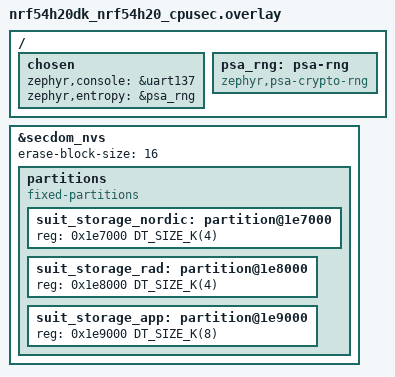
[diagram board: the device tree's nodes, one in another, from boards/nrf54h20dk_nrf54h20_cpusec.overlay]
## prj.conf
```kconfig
#
# Copyright (c) 2023 Nordic Semiconductor ASA
#
# SPDX-License-Identifier: LicenseRef-Nordic-5-Clause
#


CONFIG_ZTEST=y
CONFIG_ZTEST_NEW_API=y

CONFIG_SUIT=y
CONFIG_SUIT_UTILS=y
CONFIG_SUIT_MCI=y
CONFIG_SUIT_EXECUTION_MODE=y
CONFIG_SUIT_METADATA=y

CONFIG_ZCBOR=y
CONFIG_ZCBOR_CANONICAL=y
```

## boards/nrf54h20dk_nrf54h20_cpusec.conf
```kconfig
#
# Copyright (c) 2023 Nordic Semiconductor ASA
#
# SPDX-License-Identifier: LicenseRef-Nordic-5-Clause
#

CONFIG_NULL_POINTER_EXCEPTION_DETECTION_NONE=y
CONFIG_SERIAL=y
CONFIG_CONSOLE=y
CONFIG_UART_CONSOLE=y

# This test does not set 'IS_SECURE_DOMAIN_FW'. Hence, we need to enable the
# bare minimum configurations for running on bare metal Secure Domain.
CONFIG_SECDOM_UNIT_TEST_SUPPORT=y

# Logging and printk is using standard UART.
CONFIG_LOG_MODE_DEFERRED=y
CONFIG_LOG_BACKEND_UART=y
CONFIG_LOG_PRINTK=y
CONFIG_LOG_BUFFER_SIZE=8192


CONFIG_NULL_POINTER_EXCEPTION_DETECTION_NONE=y
CONFIG_SERIAL=y
CONFIG_CONSOLE=y
CONFIG_UART_CONSOLE=y

CONFIG_SUIT_STORAGE=y
CONFIG_SUIT_CRYPTO=y
CONFIG_SUIT_MCI_IMPL_NRF54H20_SDFW=y

CONFIG_SUIT_MPI_GENERATE=y

CONFIG_FLASH=y
```

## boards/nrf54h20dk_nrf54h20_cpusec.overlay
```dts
/*
 * Copyright (c) 2023 Nordic Semiconductor ASA
 *
 * SPDX-License-Identifier: LicenseRef-Nordic-5-Clause
 */

/ {
	chosen {
		zephyr,console = &uart137;
		zephyr,entropy = &psa_rng;
	};

	psa_rng: psa-rng {
		compatible = "zephyr,psa-crypto-rng";
		status = "okay";
	};
};

&secdom_nvs {
	erase-block-size = <16>;

	partitions {
		compatible = "fixed-partitions";
		#address-cells = <1>;
		#size-cells = <1>;

		/* Use the last 32 kB of SecDom SUIT NVM storage. */
		/* Use the first 4kB as area reserved for Secure domain. */
		suit_storage_nordic: partition@1e7000 {
			reg = <0x1e7000 DT_SIZE_K(4)>;
		};

		/* Use the next 4kB as area reserved for Radio domain. */
		suit_storage_rad: partition@1e8000 {
			reg = <0x1e8000 DT_SIZE_K(4)>;
		};

		/* Use the next 8kB as area reserved for Application domain. */
		suit_storage_app: partition@1e9000 {
			reg = <0x1e9000 DT_SIZE_K(8)>;
		};
	};
};
```

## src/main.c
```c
/*
 * Copyright (c) 2023 Nordic Semiconductor ASA
 *
 * SPDX-License-Identifier: LicenseRef-Nordic-5-Clause
 */
#include <zephyr/ztest.h>
#include <suit_mci.h>
#ifdef CONFIG_SUIT_STORAGE
#include <suit_storage.h>
#endif /* CONFIG_SUIT_STORAGE */

void test_generic_ids(void);
void test_sanity(void);
void test_api_positive_scenarios(void);
void test_topology(void);

void test_main(void)
{
#ifdef CONFIG_SUIT_STORAGE
	int ret = suit_storage_init();
	if (ret != SUIT_PLAT_SUCCESS) {
		printk("Storage init failed\n");
		return;
	}
#endif /* CONFIG_SUIT_STORAGE */

	suit_mci_init();
	test_generic_ids();
	test_sanity();
	test_api_positive_scenarios();
	test_topology();
}
```

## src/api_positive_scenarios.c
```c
/*
 * Copyright (c) 2023 Nordic Semiconductor ASA
 *
 * SPDX-License-Identifier: LicenseRef-Nordic-5-Clause
 */
#include <zephyr/ztest.h>
#include <suit_mci.h>
#ifdef CONFIG_SUIT_STORAGE
#include <suit_storage.h>
#endif /* CONFIG_SUIT_STORAGE */

#define OUTPUT_MAX_SIZE 32
static const suit_uuid_t *result_uuid[OUTPUT_MAX_SIZE];
static suit_manifest_class_info_t result_class_info[OUTPUT_MAX_SIZE];

static void *test_suit_setup(void)
{
	int ret = 0;

#ifdef CONFIG_SUIT_STORAGE
	ret = suit_storage_init();
	zassert_equal(ret, SUIT_PLAT_SUCCESS, "Unable to initialize SUIT storage");
#endif /* CONFIG_SUIT_STORAGE */

	ret = suit_mci_init();
	zassert_equal(ret, SUIT_PLAT_SUCCESS, "Unable to initialize MCI module");

	return NULL;
}

ZTEST_SUITE(mci_api_positive_scenarios_tests, NULL, test_suit_setup, NULL, NULL, NULL);

ZTEST(mci_api_positive_scenarios_tests, test_supported_manifest_class_ids_get)
{
	int rc = 0;
	size_t output_size = OUTPUT_MAX_SIZE;

	rc = suit_mci_supported_manifest_class_ids_get(result_class_info, &output_size);
	zassert_equal(rc, SUIT_PLAT_SUCCESS,
		      "suit_mci_supported_manifest_class_ids_get returned (%d)", rc);
}

ZTEST(mci_api_positive_scenarios_tests, test_invoke_order_get)
{
	int rc = 0;
	size_t output_size = OUTPUT_MAX_SIZE;

	rc = suit_mci_invoke_order_get(result_uuid, &output_size);
	zassert_equal(rc, SUIT_PLAT_SUCCESS, "suit_mci_invoke_order_get returned (%d)", rc);
}

ZTEST(mci_api_positive_scenarios_tests, test_downgrade_prevention_policy_get)
{
	int rc = 0;
	size_t output_size = OUTPUT_MAX_SIZE;

	rc = suit_mci_supported_manifest_class_ids_get(result_class_info, &output_size);
	zassert_equal(rc, SUIT_PLAT_SUCCESS,
		      "suit_mci_supported_manifest_class_ids_get returned (%d)", rc);

	for (int i = 0; i < output_size; ++i) {
		suit_downgrade_prevention_policy_t policy;

		rc = suit_mci_downgrade_prevention_policy_get(result_class_info[i].class_id,
							      &policy);
		zassert_equal(rc, SUIT_PLAT_SUCCESS,
			      "suit_mci_downgrade_prevention_policy_get returned (%d)", rc);
	}
}

ZTEST(mci_api_positive_scenarios_tests, test_independent_update_policy_get)
{
	int rc = 0;
	size_t output_size = OUTPUT_MAX_SIZE;

	rc = suit_mci_supported_manifest_class_ids_get(result_class_info, &output_size);
	zassert_equal(rc, SUIT_PLAT_SUCCESS,
		      "suit_mci_supported_manifest_class_ids_get returned (%d)", rc);

	for (int i = 0; i < output_size; ++i) {
		suit_independent_updateability_policy_t policy;

		rc = suit_mci_independent_update_policy_get(result_class_info[i].class_id, &policy);
		zassert_equal(rc, SUIT_PLAT_SUCCESS,
			      "suit_mci_independent_update_policy_get returned (%d)", rc);
	}
}

ZTEST(mci_api_positive_scenarios_tests, test_manifest_class_id_validate)
{
	int rc = 0;
	size_t output_size = OUTPUT_MAX_SIZE;

	rc = suit_mci_supported_manifest_class_ids_get(result_class_info, &output_size);
	zassert_equal(rc, SUIT_PLAT_SUCCESS,
		      "suit_mci_supported_manifest_class_ids_get returned (%d)", rc);

	for (int i = 0; i < output_size; ++i) {
		rc = suit_mci_manifest_class_id_validate(result_class_info[i].class_id);
		zassert_equal(rc, SUIT_PLAT_SUCCESS,
			      "suit_mci_manifest_class_id_validate returned (%d)", rc);
	}
}

ZTEST(mci_api_positive_scenarios_tests, test_signing_key_id_validate)
{
	int rc = 0;
	size_t output_size = OUTPUT_MAX_SIZE;

	rc = suit_mci_supported_manifest_class_ids_get(result_class_info, &output_size);
	zassert_equal(rc, SUIT_PLAT_SUCCESS,
		      "suit_mci_supported_manifest_class_ids_get returned (%d)", rc);

	for (int i = 0; i < output_size; ++i) {
		uint32_t key_id = 0;

		rc = suit_mci_signing_key_id_validate(result_class_info[i].class_id, key_id);
		zassert_true((rc == MCI_ERR_NOACCESS || rc == SUIT_PLAT_SUCCESS ||
			      rc == MCI_ERR_WRONGKEYID),
			     "suit_mci_signing_key_id_validate returned (%d)", rc);
	}
}

ZTEST(mci_api_positive_scenarios_tests, test_processor_start_rights_validate)
{
	int rc = 0;
	size_t output_size = OUTPUT_MAX_SIZE;

	rc = suit_mci_supported_manifest_class_ids_get(result_class_info, &output_size);
	zassert_equal(rc, SUIT_PLAT_SUCCESS,
		      "suit_mci_supported_manifest_class_ids_get returned (%d)", rc);

	for (int i = 0; i < output_size; ++i) {
		int processor_id = 0;

		rc = suit_mci_processor_start_rights_validate(result_class_info[i].class_id,
							      processor_id);
		zassert_true((rc == MCI_ERR_NOACCESS || rc == SUIT_PLAT_SUCCESS),
			     "suit_mci_processor_start_rights_validate returned (%d)", rc);
	}
}

ZTEST(mci_api_positive_scenarios_tests, test_memory_access_rights_validate)
{
	int rc = 0;
	size_t output_size = OUTPUT_MAX_SIZE;

	rc = suit_mci_supported_manifest_class_ids_get(result_class_info, &output_size);
	zassert_equal(rc, SUIT_PLAT_SUCCESS,
		      "suit_mci_supported_manifest_class_ids_get returned (%d)", rc);

	for (int i = 0; i < output_size; ++i) {
		void *address = &address;
		size_t mem_size = sizeof(void *);

		rc = suit_mci_memory_access_rights_validate(result_class_info[i].class_id, address,
							    mem_size);
		zassert_true((rc == MCI_ERR_NOACCESS || rc == SUIT_PLAT_SUCCESS),
			     "suit_mci_memory_access_rights_validate returned (%d)", rc);
	}
}

ZTEST(mci_api_positive_scenarios_tests, test_platform_specific_component_rights_validate)
{
	int rc = 0;
	size_t output_size = OUTPUT_MAX_SIZE;

	rc = suit_mci_supported_manifest_class_ids_get(result_class_info, &output_size);
	zassert_equal(rc, SUIT_PLAT_SUCCESS,
		      "suit_mci_supported_manifest_class_ids_get returned (%d)", rc);

	for (int i = 0; i < output_size; ++i) {
		int platform_specific_component_number = 0;

		rc = suit_mci_platform_specific_component_rights_validate(
			result_class_info[i].class_id, platform_specific_component_number);
		zassert_true((rc == MCI_ERR_NOACCESS || rc == SUIT_PLAT_SUCCESS),
			     "suit_mci_platform_specific_component_rights_validate returned (%d)",
			     rc);
	}
}

ZTEST(mci_api_positive_scenarios_tests, test_manifest_parent_child_declaration_validate)
{
	int rc = 0;
	size_t output_size = OUTPUT_MAX_SIZE;

	rc = suit_mci_supported_manifest_class_ids_get(result_class_info, &output_size);
	zassert_equal(rc, SUIT_PLAT_SUCCESS,
		      "suit_mci_supported_manifest_class_ids_get returned (%d)", rc);

	for (int i = 0; i < output_size; ++i) {
		rc = suit_mci_manifest_parent_child_declaration_validate(
			result_class_info[0].class_id, result_class_info[i].class_id);
		zassert_true((rc == MCI_ERR_NOACCESS || rc == SUIT_PLAT_SUCCESS),
			     "suit_mci_manifest_parent_child_validate returned (%d)", rc);
	}
}

ZTEST(mci_api_positive_scenarios_tests, test_manifest_process_dependency_validate)
{
	int rc = 0;
	size_t output_size = OUTPUT_MAX_SIZE;

	rc = suit_mci_supported_manifest_class_ids_get(result_class_info, &output_size);
	zassert_equal(rc, SUIT_PLAT_SUCCESS,
		      "suit_mci_supported_manifest_class_ids_get returned (%d)", rc);

	for (int i = 0; i < output_size; ++i) {
		rc = suit_mci_manifest_process_dependency_validate(result_class_info[0].class_id,
								   result_class_info[i].class_id);
		zassert_true((rc == MCI_ERR_NOACCESS || rc == SUIT_PLAT_SUCCESS),
			     "suit_mci_manifest_parent_child_validate returned (%d)", rc);
	}
}

ZTEST(mci_api_positive_scenarios_tests, test_vendor_id_for_manifest_class_id_get)
{
	int rc = 0;
	size_t output_size = OUTPUT_MAX_SIZE;

	rc = suit_mci_supported_manifest_class_ids_get(result_class_info, &output_size);
	zassert_equal(rc, SUIT_PLAT_SUCCESS,
		      "suit_mci_supported_manifest_class_ids_get returned (%d)", rc);

	for (int i = 0; i < output_size; ++i) {
		const suit_uuid_t *vendor_id = NULL;

		rc = suit_mci_vendor_id_for_manifest_class_id_get(result_class_info[i].class_id,
								  &vendor_id);
		zassert_equal(rc, SUIT_PLAT_SUCCESS,
			      "suit_mci_vendor_id_for_manifest_class_id_get returned (%d)", rc);
	}
}
```

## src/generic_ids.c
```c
/*
 * Copyright (c) 2023 Nordic Semiconductor ASA
 *
 * SPDX-License-Identifier: LicenseRef-Nordic-5-Clause
 */
#include <zephyr/ztest.h>
#include <suit_mci.h>

static void test_mci_nordic_vendor_id_value(void)
{

	suit_uuid_t expected_vid = {{0x76, 0x17, 0xda, 0xa5, 0x71, 0xfd, 0x5a, 0x85, 0x8f, 0x94,
				     0xe2, 0x8d, 0x73, 0x5c, 0xe9, 0xf4}};

	const suit_uuid_t *obtained_vid = NULL;
	mci_err_t rc = SUIT_PLAT_SUCCESS;

	rc = suit_mci_nordic_vendor_id_get(&obtained_vid);
	zassert_equal(rc, SUIT_PLAT_SUCCESS, "suit_mci_nordic_vendor_id_get returned (%d)", rc);
	zassert_not_null(obtained_vid, "obtained_vid points to NULL");
	zassert_mem_equal(obtained_vid->raw, expected_vid.raw, sizeof(((suit_uuid_t *)0)->raw),
			  "unexpected vendor_id");
}

void test_generic_ids(void)
{
	ztest_test_suite(test_suit_mci_generic_ids,
			 ztest_unit_test(test_mci_nordic_vendor_id_value));

	ztest_run_test_suite(test_suit_mci_generic_ids);
}
```

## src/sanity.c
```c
/*
 * Copyright (c) 2023 Nordic Semiconductor ASA
 *
 * SPDX-License-Identifier: LicenseRef-Nordic-5-Clause
 */
#include <zephyr/ztest.h>
#include <suit_mci.h>
#include <suit_execution_mode.h>

#define OUTPUT_MAX_SIZE 32
static const suit_uuid_t *result_uuid[OUTPUT_MAX_SIZE];
static suit_manifest_class_info_t result_class_info[OUTPUT_MAX_SIZE];

static void test_null_pointers(void)
{
	const suit_manifest_class_id_t unsupported_manifest_class_id = {
		{'u', 'n', 's', 'u', 'p', 'p', 'o', 'r', 't', 'e', 'd', '!', '!', '!', ' ', ' '}};
	size_t output_size = OUTPUT_MAX_SIZE;
	uint32_t key_id = 0;
	int processor_id = 0;
	void *mem_address = &mem_address;
	size_t mem_size = sizeof(mem_address);
	int platform_specific_component_number = 0;
	suit_downgrade_prevention_policy_t policy;
	suit_independent_updateability_policy_t update_policy;
	int rc = SUIT_PLAT_SUCCESS;

	rc = suit_mci_nordic_vendor_id_get(NULL);
	zassert_equal(rc, SUIT_PLAT_ERR_INVAL, "suit_mci_nordic_vendor_id_get returned (%d)", rc);

	output_size = OUTPUT_MAX_SIZE;
	rc = suit_mci_supported_manifest_class_ids_get(NULL, &output_size);
	zassert_equal(rc, SUIT_PLAT_ERR_INVAL,
		      "suit_mci_supported_manifest_class_ids_get returned (%d)", rc);

	rc = suit_mci_supported_manifest_class_ids_get(result_class_info, NULL);
	zassert_equal(rc, SUIT_PLAT_ERR_INVAL,
		      "suit_mci_supported_manifest_class_ids_get returned (%d)", rc);

	output_size = OUTPUT_MAX_SIZE;
	rc = suit_mci_invoke_order_get(NULL, &output_size);
	zassert_equal(rc, SUIT_PLAT_ERR_INVAL, "suit_mci_invoke_order_get returned (%d)", rc);

	rc = suit_mci_invoke_order_get(result_uuid, NULL);
	zassert_equal(rc, SUIT_PLAT_ERR_INVAL, "suit_mci_invoke_order_get returned (%d)", rc);

	rc = suit_mci_downgrade_prevention_policy_get(NULL, &policy);
	zassert_equal(rc, SUIT_PLAT_ERR_INVAL,
		      "suit_mci_downgrade_prevention_policy_get returned (%d)", rc);

	rc = suit_mci_downgrade_prevention_policy_get(&unsupported_manifest_class_id, NULL);
	zassert_equal(rc, SUIT_PLAT_ERR_INVAL,
		      "suit_mci_downgrade_prevention_policy_get returned (%d)", rc);

	rc = suit_mci_independent_update_policy_get(NULL, &update_policy);
	zassert_equal(rc, SUIT_PLAT_ERR_INVAL,
		      "suit_mci_independent_update_policy_get returned (%d)", rc);

	rc = suit_mci_independent_update_policy_get(&unsupported_manifest_class_id, NULL);
	zassert_equal(rc, SUIT_PLAT_ERR_INVAL,
		      "suit_mci_independent_update_policy_get returned (%d)", rc);

	rc = suit_mci_signing_key_id_validate(NULL, key_id);
	zassert_equal(rc, SUIT_PLAT_ERR_INVAL, "suit_mci_signing_key_id_validate returned (%d)",
		      rc);

	rc = suit_mci_manifest_class_id_validate(NULL);
	zassert_equal(rc, SUIT_PLAT_ERR_INVAL, "suit_mci_manifest_class_id_validate returned (%d)",
		      rc);

	rc = suit_mci_processor_start_rights_validate(NULL, processor_id);
	zassert_equal(rc, SUIT_PLAT_ERR_INVAL,
		      "suit_mci_processor_start_rights_validate returned (%d)", rc);

	rc = suit_mci_memory_access_rights_validate(NULL, mem_address, mem_size);
	zassert_equal(rc, SUIT_PLAT_ERR_INVAL,
		      "suit_mci_memory_access_rights_validate returned (%d)", rc);

	rc = suit_mci_memory_access_rights_validate(&unsupported_manifest_class_id, NULL, mem_size);
	zassert_equal(rc, SUIT_PLAT_ERR_INVAL,
		      "suit_mci_memory_access_rights_validate returned (%d)", rc);

	rc = suit_mci_platform_specific_component_rights_validate(
		NULL, platform_specific_component_number);
	zassert_equal(rc, SUIT_PLAT_ERR_INVAL,
		      "suit_mci_platform_specific_component_rights_validate returned (%d)", rc);

	rc = suit_mci_manifest_parent_child_declaration_validate(&unsupported_manifest_class_id, NULL);
	zassert_equal(rc, SUIT_PLAT_ERR_INVAL,
		      "suit_mci_manifest_parent_child_validate returned (%d)", rc);

	rc = suit_mci_manifest_parent_child_declaration_validate(NULL, &unsupported_manifest_class_id);
	zassert_equal(rc, SUIT_PLAT_ERR_INVAL,
		      "suit_mci_manifest_parent_child_validate returned (%d)", rc);

	rc = suit_mci_manifest_process_dependency_validate(&unsupported_manifest_class_id, NULL);
	zassert_equal(rc, SUIT_PLAT_ERR_INVAL,
		      "suit_mci_manifest_parent_child_validate returned (%d)", rc);

	rc = suit_mci_manifest_process_dependency_validate(NULL, &unsupported_manifest_class_id);
	zassert_equal(rc, SUIT_PLAT_ERR_INVAL,
		      "suit_mci_manifest_parent_child_validate returned (%d)", rc);

	rc = suit_mci_vendor_id_for_manifest_class_id_get(NULL, result_uuid);
	zassert_equal(rc, SUIT_PLAT_ERR_INVAL,
		      "suit_mci_vendor_id_for_manifest_class_id_get returned (%d)", rc);

	rc = suit_mci_vendor_id_for_manifest_class_id_get(&unsupported_manifest_class_id, NULL);
	zassert_equal(rc, SUIT_PLAT_ERR_INVAL,
		      "suit_mci_vendor_id_for_manifest_class_id_get returned (%d)", rc);
}

static void test_invalid_params(void)
{
	void *mem_address = &mem_address;
	size_t mem_size = sizeof(mem_address);
	int rc = SUIT_PLAT_SUCCESS;

	rc = suit_mci_memory_access_rights_validate(NULL, mem_address, mem_size);
	zassert_equal(rc, SUIT_PLAT_ERR_INVAL,
		      "suit_mci_memory_access_rights_validate returned (%d)", rc);
}

static void test_output_buffer_too_small(void)
{
	size_t output_size = OUTPUT_MAX_SIZE;
	size_t supported_manifest_count = 0;
	size_t invokable_manifest_count = 0;
	int rc = SUIT_PLAT_SUCCESS;

	output_size = OUTPUT_MAX_SIZE;
	rc = suit_mci_supported_manifest_class_ids_get(result_class_info, &output_size);
	zassert_equal(rc, SUIT_PLAT_SUCCESS,
		      "suit_mci_supported_manifest_class_ids_get returned (%d), isn't %d manifests "
		      "enough?!",
		      rc, OUTPUT_MAX_SIZE);
	supported_manifest_count = output_size;

	output_size = supported_manifest_count;
	rc = suit_mci_supported_manifest_class_ids_get(result_class_info, &output_size);
	zassert_equal(rc, SUIT_PLAT_SUCCESS,
		      "suit_mci_supported_manifest_class_ids_get returned (%d)", rc);

	if (supported_manifest_count > 1) {
		output_size = supported_manifest_count - 1;
		rc = suit_mci_supported_manifest_class_ids_get(result_class_info, &output_size);
		zassert_equal(rc, SUIT_PLAT_ERR_SIZE,
			      "suit_mci_supported_manifest_class_ids_get returned (%d)", rc);
	}

	if (supported_manifest_count > 0) {
		output_size = 0;
		rc = suit_mci_supported_manifest_class_ids_get(result_class_info, &output_size);
		zassert_equal(rc, SUIT_PLAT_ERR_SIZE,
			      "suit_mci_supported_manifest_class_ids_get returned (%d)", rc);
	}

	suit_execution_mode_set(EXECUTION_MODE_INVOKE);
	output_size = OUTPUT_MAX_SIZE;
	rc = suit_mci_invoke_order_get(result_uuid, &output_size);
	zassert_equal(rc, SUIT_PLAT_SUCCESS,
		      "suit_mci_invoke_order_get returned (%d), isn't %d manifests enough?!", rc,
		      OUTPUT_MAX_SIZE);
	invokable_manifest_count = output_size;

	output_size = invokable_manifest_count;
	rc = suit_mci_invoke_order_get(result_uuid, &output_size);
	zassert_equal(rc, SUIT_PLAT_SUCCESS, "suit_mci_invoke_order_get returned (%d)", rc);


	if (invokable_manifest_count > 1) {
		output_size = invokable_manifest_count - 1;
		rc = suit_mci_invoke_order_get(result_uuid, &output_size);
		zassert_equal(rc, SUIT_PLAT_ERR_SIZE, "suit_mci_invoke_order_get returned (%d)",
			      rc);
	}

	if (invokable_manifest_count > 0) {
		output_size = 0;
		rc = suit_mci_invoke_order_get(result_uuid, &output_size);
		zassert_equal(rc, SUIT_PLAT_ERR_SIZE, "suit_mci_invoke_order_get returned (%d)",
			      rc);
	}
}

void test_sanity(void)
{
	ztest_test_suite(test_suit_mci_sanity, ztest_unit_test(test_null_pointers),
			 ztest_unit_test(test_invalid_params),
			 ztest_unit_test(test_output_buffer_too_small));

	ztest_run_test_suite(test_suit_mci_sanity);
}
```

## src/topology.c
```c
/*
 * Copyright (c) 2023 Nordic Semiconductor ASA
 *
 * SPDX-License-Identifier: LicenseRef-Nordic-5-Clause
 */
#include <zephyr/ztest.h>
#include <suit_mci.h>
#ifdef CONFIG_SUIT_STORAGE
#include <suit_storage.h>
#endif /* CONFIG_SUIT_STORAGE */

#define OUTPUT_MAX_SIZE 32
static const suit_uuid_t *result_uuid[OUTPUT_MAX_SIZE];
static suit_manifest_class_info_t result_class_info[OUTPUT_MAX_SIZE];

static int compare_manifest_class_id(const suit_manifest_class_id_t *manifest_class_id1,
				     const suit_manifest_class_id_t *manifest_class_id2)
{
	return memcmp(manifest_class_id1->raw, manifest_class_id2->raw,
		      sizeof(((suit_manifest_class_id_t *)0)->raw));
}

static void *test_suit_setup(void)
{
	int ret = 0;

#ifdef CONFIG_SUIT_STORAGE
	ret = suit_storage_init();
	zassert_equal(ret, SUIT_PLAT_SUCCESS, "Unable to initialize SUIT storage");
#endif /* CONFIG_SUIT_STORAGE */

	ret = suit_mci_init();
	zassert_equal(ret, SUIT_PLAT_SUCCESS, "Unable to initialize MCI module");

	return NULL;
}

ZTEST_SUITE(mci_topology_tests, NULL, test_suit_setup, NULL, NULL, NULL);

ZTEST(mci_topology_tests, test_duplicate_ids_in_supported_manifest)
{
	int rc = SUIT_PLAT_SUCCESS;
	size_t output_size = OUTPUT_MAX_SIZE;

	rc = suit_mci_supported_manifest_class_ids_get(result_class_info, &output_size);
	zassert_equal(rc, SUIT_PLAT_SUCCESS,
		      "suit_mci_supported_manifest_class_ids_get returned (%d)", rc);

	for (int i = 0; i < output_size; ++i) {
		for (int j = i + 1; j < output_size; ++j) {
			rc = compare_manifest_class_id(result_class_info[i].class_id,
						       result_class_info[j].class_id);
			zassert_true((rc != 0), "the same uuid used for two manifests");
		}
	}
}

ZTEST(mci_topology_tests, test_duplicate_ids_in_invoke_order)
{
	int rc = SUIT_PLAT_SUCCESS;
	size_t output_size = OUTPUT_MAX_SIZE;

	rc = suit_mci_invoke_order_get(result_uuid, &output_size);
	zassert_equal(rc, SUIT_PLAT_SUCCESS, "suit_mci_invoke_order_get returned (%d)", rc);

	for (int i = 0; i < output_size; ++i) {
		for (int j = i + 1; j < output_size; ++j) {
			rc = compare_manifest_class_id(result_class_info[i].class_id,
						       result_class_info[j].class_id);
			zassert_true((rc != 0), "the same uuid used for two manifests");
		}
	}
}
```
